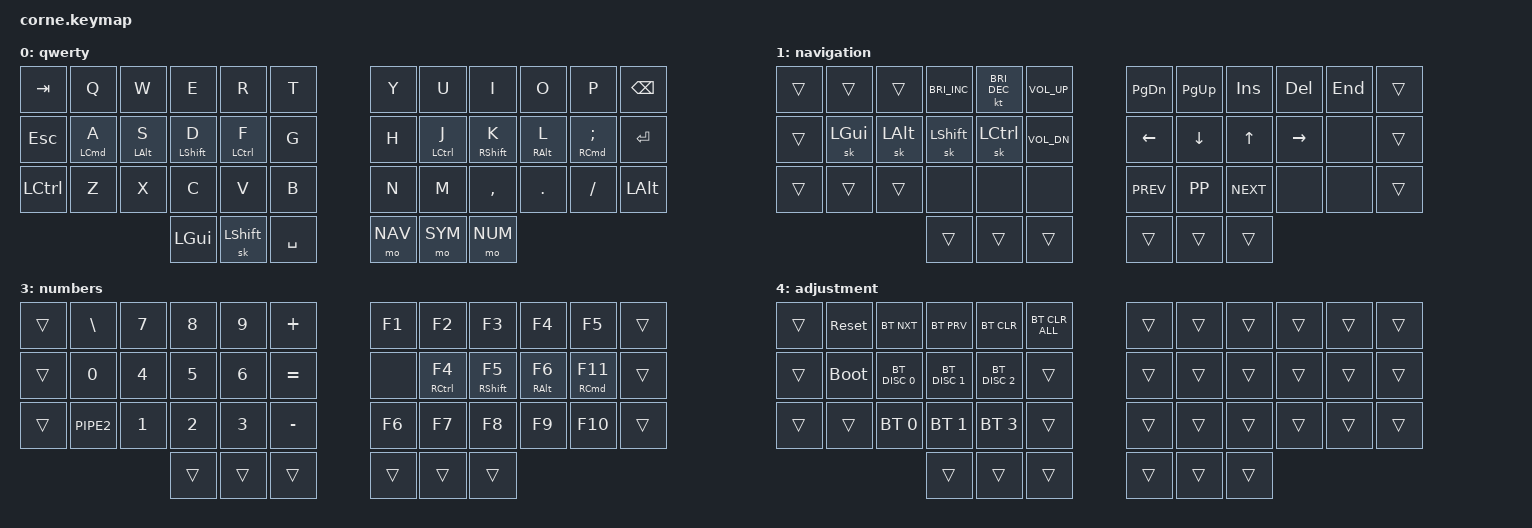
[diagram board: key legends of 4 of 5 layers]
#include <behaviors.dtsi>
#include <dt-bindings/zmk/bt.h>
#include <dt-bindings/zmk/keys.h>

// Layer Definitions

#define QWERTY 0
#define NAV 1
#define SYM 2
#define NUM 3

// Behavior configuration

&sk {
    release-after-ms = <300>;
    quick-release;
};

&sl { release-after-ms = <1000>; };

&caps_word { continue-list = <UNDERSCORE MINUS>; };

// Keymap configuration

/ {
    behaviors {
        shftcw: shift_capsword {
            compatible = "zmk,behavior-tap-dance";
            label = "SHIFT_CAPS_WORD";
            #binding-cells = <0>;
            tapping-term-ms = <200>;
            bindings = <&sk LSHIFT>, <&caps_word>;
        };

        hml: hml {
            compatible = "zmk,behavior-hold-tap";
            label = "HML";
            bindings = <&kp>, <&kp>;

            #binding-cells = <2>;
            tapping-term-ms = <280>;
            quick-tap-ms = <175>;
            require-prior-idle-ms = <120>;
            flavor = "balanced";
            hold-trigger-key-positions = <6 18 30 31 32 33 34 35 23 22 21 19 20 7 8 9 10 11>;
            hold-trigger-on-release;
        };

        hmr: hmr {
            compatible = "zmk,behavior-hold-tap";
            label = "HMR";
            bindings = <&kp>, <&kp>;

            #binding-cells = <2>;
            tapping-term-ms = <280>;
            quick-tap-ms = <175>;
            require-prior-idle-ms = <120>;
            flavor = "balanced";
            hold-trigger-key-positions = <2 0 1 2 3 4 5 12 13 14 15 16 17 24 25 26 27 28 29>;
            hold-trigger-on-release;
            hold-while-undecided;
        };
    };

    /*                KEY POSITIONS
  ╭──────────────────────╮ ╭───────────────────────╮
  │  0   1   2   3   4  5│ │  6  7   8   9   10  11│
  │ 12  13  14  15  16 17│ │ 18  19  20  21  22  23│
  │ 24  25  26  27  28 29│ │ 30  31  32  33  34  35│
  ╰─────────╮   36  37 38│ │ 39  40  41╭───────────╯
            ╰────────────╯ ╰───────────╯            */

    combos {
        compatible = "zmk,combos";

        combo_esc {
            timeout-ms = <60>;
            key-positions = <4 3>;
            bindings = <&kp ESC>;
            require-prior-idle-ms = <60>;
        };

        combo_tab {
            timeout-ms = <60>;
            key-positions = <27 28>;
            bindings = <&kp TAB>;
            require-prior-idle-ms = <60>;
        };

        combo_ret {
            timeout-ms = <60>;
            key-positions = <31 32>;
            bindings = <&kp RET>;
            require-prior-idle-ms = <60>;
        };

        combo_bspc {
            bindings = <&kp BACKSPACE>;
            key-positions = <7 8>;
            timeout-ms = <60>;
            require-prior-idle-ms = <60>;
        };

        combo_adj {
            bindings = <&mo 4>;
            key-positions = <36 41>;
            timeout-ms = <60>;
            require-prior-idle-ms = <60>;
        };
    };

    keymap {
        compatible = "zmk,keymap";

        qwerty {
            bindings = <
&kp TAB    &kp Q        &kp W            &kp E          &kp R           &kp T        &kp Y    &kp U         &kp I         &kp O             &kp P           &kp BACKSPACE
&kp ESC    &hml LCMD A  &hml LEFT_ALT S  &hml LSHIFT D  &hml LCTRL F    &kp G        &kp H    &hmr LCTRL J  &hmr RSHFT K  &hmr RIGHT_ALT L  &hmr RCMD SEMI  &kp ENTER
&kp LCTRL  &kp Z        &kp X            &kp C          &kp V           &kp B        &kp N    &kp M         &kp COMMA     &kp DOT           &kp FSLH        &kp LALT
                                         &kp LGUI       &sk LEFT_SHIFT  &kp SPACE    &mo NAV  &mo SYM       &mo NUM
            >;
        };

        navigation {
            bindings = <
&trans  &trans    &trans    &kp C_BRIGHTNESS_INC  &kt C_BRIGHTNESS_DEC  &kp C_VOL_UP    &kp PAGE_DOWN  &kp PAGE_UP  &kp INSERT  &kp DELETE  &kp END  &trans
&trans  &sk LGUI  &sk LALT  &sk LSHFT             &sk LCTRL             &kp C_VOL_DN    &kp LEFT       &kp DOWN     &kp UP      &kp RIGHT   &none    &trans
&trans  &trans    &trans    &none                 &none                 &none           &kp K_PREV     &kp K_PP     &kp K_NEXT  &none       &none    &trans
                            &trans                &trans                &trans          &trans         &trans       &trans
            >;
        };

        symbols {
            bindings = <
&trans  &kp EXCL       &kp AT        &kp LBRC              &kp RBRC               &kp HASH     &none     &kp SEMI       &kp COLON  &kp UNDER          &kp MINUS         &trans
&trans  &kp DOLLAR     &kp PERCENT   &kp LEFT_PARENTHESIS  &kp RIGHT_PARENTHESIS  &kp EQUAL    &none     &kp GRAVE      &kp TILDE  &kp DOUBLE_QUOTES  &kp SINGLE_QUOTE  &trans
&trans  &kp AMPERSAND  &kp ASTERISK  &kp LEFT_BRACKET      &kp RIGHT_BRACKET      &kp CARET    &kp PIPE  &kp BACKSLASH  &none      &none              &trans            &trans
                                     &trans                &trans                 &trans       &trans    &trans
            >;
        };

        numbers {
            bindings = <
&trans  &kp BACKSLASH  &kp N7  &kp N8  &kp N9  &kp PLUS     &kp F1  &kp F2         &kp F3         &kp F4        &kp F5         &trans
&trans  &kp N0         &kp N4  &kp N5  &kp N6  &kp EQUAL    &none   &hmr RCTRL F4  &hmr RSHFT F5  &hmr RALT F6  &hmr RCMD F11  &trans
&trans  &kp PIPE2      &kp N1  &kp N2  &kp N3  &kp MINUS    &kp F6  &kp F7         &kp F8         &kp F9        &kp F10        &trans
                               &trans  &trans  &trans       &trans  &trans         &trans
            >;
        };

        adjustment {
            bindings = <
&trans  &sys_reset   &bt BT_NXT     &bt BT_PRV     &bt BT_CLR     &bt BT_CLR_ALL    &trans  &trans  &trans  &trans  &trans  &trans
&trans  &bootloader  &bt BT_DISC 0  &bt BT_DISC 1  &bt BT_DISC 2  &trans            &trans  &trans  &trans  &trans  &trans  &trans
&trans  &trans       &bt BT_SEL 0   &bt BT_SEL 1   &bt BT_SEL 3   &trans            &trans  &trans  &trans  &trans  &trans  &trans
                                    &trans         &trans         &trans            &trans  &trans  &trans
            >;
        };
    };
};
